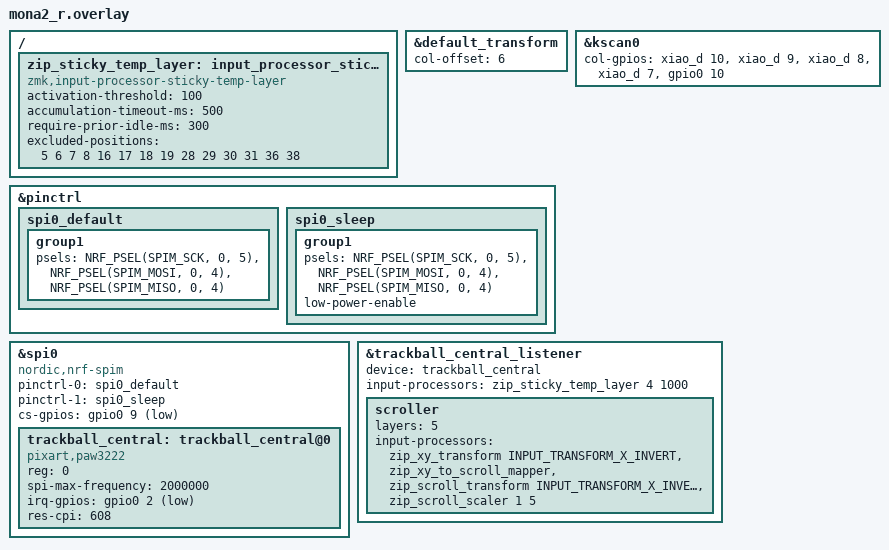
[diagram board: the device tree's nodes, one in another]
#include "mona2.dtsi"
// <input/processors.dtsi> は mona2.dtsi が既に include している
#include <zephyr/dt-bindings/input/input-event-codes.h>


&default_transform {
    col-offset = <6>;
};

&kscan0 {
        col-gpios
            = <&xiao_d 10 GPIO_ACTIVE_HIGH>
            , <&xiao_d 9 GPIO_ACTIVE_HIGH> 
            , <&xiao_d 8 GPIO_ACTIVE_HIGH> 
            , <&xiao_d 7 GPIO_ACTIVE_HIGH> 
            , <&gpio0 10 GPIO_ACTIVE_HIGH>
            ;
};


&pinctrl {
    spi0_default: spi0_default {    //通常時(SPI通信中)のピン構成
        group1 {
            psels = <NRF_PSEL(SPIM_SCK, 0, 5)>, //P0.05を指定(SCLK)
                <NRF_PSEL(SPIM_MOSI, 0, 4)>,    //P0.04を指定(SDIOだからMOSI,MISO両方の役割を担う)
                <NRF_PSEL(SPIM_MISO, 0, 4)>;
        };
    };

    spi0_sleep: spi0_sleep {    //スリープ時のピン構成(省電力)
        group1 {
            psels = <NRF_PSEL(SPIM_SCK, 0, 5)>,
                <NRF_PSEL(SPIM_MOSI, 0, 4)>,
                <NRF_PSEL(SPIM_MISO, 0, 4)>;
            low-power-enable;
        };
    };
};


&spi0 {
    status = "okay";
    compatible = "nordic,nrf-spim"; //マイコンがnRFシリーズ
    pinctrl-0 = <&spi0_default>;
    pinctrl-1 = <&spi0_sleep>;
    pinctrl-names = "default", "sleep";
    cs-gpios = <&gpio0 9 GPIO_ACTIVE_LOW>;  //P0.09を指定(CS)

    trackball_central: trackball_central@0 {
        status = "okay";
        compatible = "pixart,paw3222";  //トラボセンサ用のドライバとバインド
        reg = <0>;
        spi-max-frequency = <2000000>;
        irq-gpios = <&gpio0 2 (GPIO_ACTIVE_LOW | GPIO_PULL_UP)>; //P0.02を指定(MOTION)

        // PAW3222 の解像度は 38 CPI 刻みで、有効範囲は 608 (16*38) 〜 4826 (127*38)。
        // 範囲外だと paw3222.c の BUILD_ASSERT でビルドが失敗する
        // (実行時に paw32xx_set_resolution へ届く前に止まる)。
        // 608 は純正 PMW3610 版の cpi=600 に最も近い有効値。
        res-cpi = <608>;
    };
};


// Overrides for the input listener node
// === オートマウスレイヤー(BALL=4)の制御 ===
// ZMK 標準の zip_temp_layer には2つ問題があった。
//  1. 移動量を見ず 1 カウントでも発動するため、タイピング中の振動や
//     ボールの転がりで BALL 層に入ってしまう。
//  2. excluded-positions に挙げたキーを押しても無効化タイマーが延長されない。
//     再セットしているのは temp_layer_handle_event() の中の 1 行だけで、
//     これは入力リスナー経由でポインタ入力が来たときしか呼ばれない。
//     キー押下は handle_position_state_changed という別経路で届くが、
//     そこには解除の処理しか無い。結果、ボールを止めてクリックを連打すると
//     最後のボール移動からタイムアウト時間で層が落ちる。
//
// 1 は以前 gohanda11/zmk-input-processor-threshold-temp-layer で対処していたが、
// 2 も直すため、このリポジトリ自身の src/input_processor_sticky_temp_layer.c に
// 一本化した (Keyball39 側と同一ファイル)。ZMK 公式の実装をベースにしており、
// 排他制御・work 経由のレイヤー操作・zmk_layer_state_changed の購読による
// 整合取り・多重インスタンス対応をそのまま引き継いでいる。
/ {
    zip_sticky_temp_layer: input_processor_sticky_temp_layer {
        compatible = "zmk,input-processor-sticky-temp-layer";
        #input-processor-cells = <2>;

        // 発動に必要な累積移動距離 (センサーのカウント数)。
        // res-cpi = 608 なので 1 カウント ≒ 0.042mm → 100 ≒ 4.2mm。
        // 意図的にボールを回せば超え、振動レベルでは超えない想定。
        //
        // 累積は X/Y の相対移動イベントごとに |value| を足すマンハッタン距離。
        // 以前使っていた gohanda11 版も、関数内 static の持ち方のせいで
        // 八角形近似が効かず実質同じ計算だったので、体感は変わらない。
        activation-threshold = <100>;

        // 500ms 動きが無ければ累積を捨てる。
        // 以前の実装には減衰が無く、レイヤーが一度も発動しない限り累積が
        // 増え続けるため、わずかなドリフトの積み重ねでいつか発動していた
        // (手を置いて読んでいるだけのときなど)。これで「一続きの動きで
        // 4.2mm」という本来の意味になる。長すぎると感じたら縮める。
        accumulation-timeout-ms = <500>;

        // 直前の打鍵から 300ms 以内はボールを動かしても BALL 層へ入らない。
        // この判定は蓄積処理より手前にあるため、打鍵中の振動は累積にも入らない。
        require-prior-idle-ms = <300>;

        // ここに挙げた位置「以外」のキーを押すと BALL 層を即座に解除する。
        // = BALL 層で実際に使うキーだけを列挙 (位置番号は 0..41)。
        //    5  6  7  8      LC(W) 中クリック MB4 MB5
        //   16 17 18 19      ← 左クリック 右クリック →
        //   28 29 30 31      MO(SCROLL) スクロール下 スクロール上 LCTRL
        //   36               左親指 td_lctl (hold=LCTRL)
        //   38               左親指 mt LSHFT LANG2 (hold=LSHFT)
        //
        // 36/38 を入れているのは Ctrl+クリック / Shift+クリックのため。
        // これらを外すと、修飾キーを押した瞬間に BALL 層が解除され、
        // 続くクリックが L0 の &kp J などになってしまう。
        //
        // sticky 版ではこれらのキーの押下・離上で無効化タイマーが延長される。
        // ボールを止めてクリックを連打しても層が落ちない。
        excluded-positions = <5 6 7 8 16 17 18 19 28 29 30 31 36 38>;
    };
};

&trackball_central_listener {
    status = "okay";
    device = <&trackball_central>;

    // ボール移動で BALL(4) 層へ。ボールが止まり、かつ BALL 層のキーも
    // 操作されなくなってから 1000ms で復帰する。
    input-processors = <&zip_sticky_temp_layer 4 1000>;

    scroller {
        layers = <5>;                                       //SCROLL 層
        input-processors = 
            // <&zip_xy_transform INPUT_TRANSFORM_XY_SWAP>,        //X軸とY軸の入れ替え
            <&zip_xy_transform INPUT_TRANSFORM_X_INVERT>,       //X軸反転
            <&zip_xy_to_scroll_mapper>,                         //スクロールモードに変更
            <&zip_scroll_transform INPUT_TRANSFORM_X_INVERT>,   //スクロールのX軸反転
            <&zip_scroll_scaler 1 5>;                           //スクロール量を1/5倍 (セルは <乗数 除数>)
    };

};
